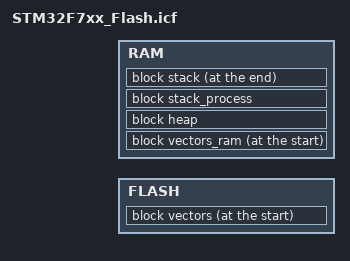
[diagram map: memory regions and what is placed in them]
/*********************************************************************
*                    SEGGER Microcontroller GmbH                     *
*                        The Embedded Experts                        *
**********************************************************************
*                                                                    *
*            (c) 2014 - 2021 SEGGER Microcontroller GmbH             *
*                                                                    *
*       www.segger.com     Support: support@segger.com               *
*                                                                    *
**********************************************************************
*                                                                    *
* All rights reserved.                                               *
*                                                                    *
* Redistribution and use in source and binary forms, with or         *
* without modification, are permitted provided that the following    *
* condition is met:                                                  *
*                                                                    *
* - Redistributions of source code must retain the above copyright   *
*   notice, this condition and the following disclaimer.             *
*                                                                    *
* THIS SOFTWARE IS PROVIDED BY THE COPYRIGHT HOLDERS AND             *
* CONTRIBUTORS "AS IS" AND ANY EXPRESS OR IMPLIED WARRANTIES,        *
* INCLUDING, BUT NOT LIMITED TO, THE IMPLIED WARRANTIES OF           *
* MERCHANTABILITY AND FITNESS FOR A PARTICULAR PURPOSE ARE           *
* DISCLAIMED. IN NO EVENT SHALL SEGGER Microcontroller BE LIABLE FOR *
* ANY DIRECT, INDIRECT, INCIDENTAL, SPECIAL, EXEMPLARY, OR           *
* CONSEQUENTIAL DAMAGES (INCLUDING, BUT NOT LIMITED TO, PROCUREMENT  *
* OF SUBSTITUTE GOODS OR SERVICES; LOSS OF USE, DATA, OR PROFITS;    *
* OR BUSINESS INTERRUPTION) HOWEVER CAUSED AND ON ANY THEORY OF      *
* LIABILITY, WHETHER IN CONTRACT, STRICT LIABILITY, OR TORT          *
* (INCLUDING NEGLIGENCE OR OTHERWISE) ARISING IN ANY WAY OUT OF THE  *
* USE OF THIS SOFTWARE, EVEN IF ADVISED OF THE POSSIBILITY OF SUCH   *
* DAMAGE.                                                            *
*                                                                    *
**********************************************************************
-------------------------- END-OF-HEADER -----------------------------

File    : STM32F7xx_Flash.icf
Purpose : STM32F7xx linker script for application placement in Flash,
          for use with the SEGGER Linker.
Maps    : STM32F722ICKx, STM32F722ICTx, STM32F722IEKx, STM32F722IETx, 
          STM32F722RCTx, STM32F722RETx, STM32F722VCTx, STM32F722VETx, 
          STM32F722ZCTx, STM32F722ZETx, STM32F723ICKx, STM32F723ICTx, 
          STM32F723IEKx, STM32F723IETx, STM32F723VEYx, STM32F723ZCIx, 
          STM32F723ZCTx, STM32F723ZEIx, STM32F723ZETx, STM32F730I8Kx, 
          STM32F730R8Tx, STM32F730V8Tx, STM32F730Z8Tx, STM32F732IEKx, 
          STM32F732IETx, STM32F732RETx, STM32F732VETx, STM32F732ZETx, 
          STM32F733IEKx, STM32F733IETx, STM32F733VETx, STM32F733VEYx, 
          STM32F733ZEKx, STM32F733ZETx, STM32F745IEKx, STM32F745IETx, 
          STM32F745IGKx, STM32F745IGTx, STM32F745VEHx, STM32F745VETx, 
          STM32F745VGHx, STM32F745VGTx, STM32F745ZETx, STM32F745ZGTx, 
          STM32F746BETx, STM32F746BGTx, STM32F746IEKx, STM32F746IETx, 
          STM32F746IGKx, STM32F746IGTx, STM32F746NEHx, STM32F746NGHx, 
          STM32F746VEHx, STM32F746VETx, STM32F746VGHx, STM32F746VGTx, 
          STM32F746ZETx, STM32F746ZEYx, STM32F746ZGTx, STM32F746ZGYx, 
          STM32F750N8Hx, STM32F750V8Tx, STM32F750Z8Tx, STM32F756BGTx, 
          STM32F756IGKx, STM32F756IGTx, STM32F756NGHx, STM32F756VGHx, 
          STM32F756VGTx, STM32F756ZGTx, STM32F756ZGYx, STM32F765BGTx, 
          STM32F765BITx, STM32F765IGKx, STM32F765IGTx, STM32F765IIKx, 
          STM32F765IITx, STM32F765NGHx, STM32F765NIHx, STM32F765VGTx, 
          STM32F765VITx, STM32F765ZGTx, STM32F765ZITx, STM32F767BGTx, 
          STM32F767BITx, STM32F767IGKx, STM32F767IGTx, STM32F767IIKx, 
          STM32F767IITx, STM32F767NGHx, STM32F767NIHx, STM32F767VGTx, 
          STM32F767VITx, STM32F767ZGTx, STM32F767ZITx, STM32F768AIYx, 
          STM32F769AGYx, STM32F769AIYx, STM32F769BGTx, STM32F769BITx, 
          STM32F769IGTx, STM32F769IITx, STM32F769NGHx, STM32F769NIHx, 
          STM32F777BITx, STM32F777IIKx, STM32F777IITx, STM32F777NIHx, 
          STM32F777VITx, STM32F777ZITx, STM32F778AIYx, STM32F779AIYx, 
          STM32F779BITx, STM32F779IITx, STM32F779NIHx
Literature:
  [1]  SEGGER Linker User Guide (https://www.segger.com/doc/UM20005_Linker.html)
  [2]  SEGGER Linker Section Placement (https://wiki.segger.com/SEGGER_Linker_Script_Files)
*/

define memory with size = 4G;

//
// Combined regions per memory type
//
define region FLASH = FLASH1;
define region RAM   = DTCM_RAM1 + RAM1;

//
// Block definitions
//
define block vectors                        { section .vectors };                                   // Vector table section
define block vectors_ram                    { section .vectors_ram };                               // Vector table section
define block ctors                          { section .ctors,     section .ctors.*, block with         alphabetical order { init_array } };
define block dtors                          { section .dtors,     section .dtors.*, block with reverse alphabetical order { fini_array } };
define block exidx                          { section .ARM.exidx, section .ARM.exidx.* };
define block tbss                           { section .tbss,      section .tbss.*  };
define block tdata                          { section .tdata,     section .tdata.* };
define block tls                            { block tbss, block tdata };
define block tdata_load                     { copy of block tdata };
define block heap  with size = __HEAPSIZE__,  alignment = 8, /* fill =0x00, */ readwrite access { };
define block stack_process with size = __STACKSIZE_PROCESS__, alignment = 8, /* fill =0xCD, */ readwrite access { };
define block stack with size = __STACKSIZE__, alignment = 8, /* fill =0xCD, */ readwrite access { };
//
// Explicit initialization settings for sections
// Packing options for initialize by copy: packing=auto/lzss/zpak/packbits
//
do not initialize                           { section .non_init, section .non_init.*, section .*.non_init, section .*.non_init.* };
do not initialize                           { section .no_init, section .no_init.*, section .*.no_init, section .*.no_init.* };   // Legacy sections, kept for backwards compatibility
do not initialize                           { section .noinit, section .noinit.*, section .*.noinit, section .*.noinit.* };       // Legacy sections, used by some SDKs/HALs
do not initialize                           { block vectors_ram };
initialize by copy with packing=auto        { section .data, section .data.*, section .*.data, section .*.data.* };               // Static data sections
initialize by copy with packing=auto        { section .fast, section .fast.* };                                                   // "RAM Code" sections
initialize by symbol __SEGGER_init_heap     { block heap  };                                        // Init the heap if there is one
initialize by symbol __SEGGER_init_ctors    { block ctors };                                        // Call constructors for global objects which need to be constructed before reaching main (if any). Make sure this is done after setting up heap.

//
// Explicit placement in FLASHn
//
place in ITCM_FLASH1                        { section .ITCM_FLASH1, section .ITCM_FLASH1.* };
place in FLASH1                             { section .FLASH1, section .FLASH1.* };
//
// FLASH Placement
//
place at start of FLASH                     { block vectors };                                      // Vector table section
place in FLASH with minimum size order      { block tdata_load,                                     // Thread-local-storage load image
                                              block exidx,                                          // ARM exception unwinding block
                                              block ctors,                                          // Constructors block
                                              block dtors,                                          // Destructors block
                                              readonly,                                             // Catch-all for readonly data (e.g. .rodata, .srodata)
                                              readexec                                              // Catch-all for (readonly) executable code (e.g. .text)
                                            };

//
// Explicit placement in RAMn
//
place in ITCM_RAM1                          { section .ITCM_RAM1, section .ITCM_RAM1.* };
place in DTCM_RAM1                          { section .DTCM_RAM1, section .DTCM_RAM1.* };
place in RAM1                               { section .RAM1, section .RAM1.* };


place in RAM1                               { section .fast, section .fast.*};                      // Place RAM Functions in executable region//
// RAM Placement
//
place at start of RAM                       { block vectors_ram };
place in RAM with auto order                { block tls,                                            // Thread-local-storage block
                                              readwrite,                                            // Catch-all for initialized/uninitialized data sections (e.g. .data, .noinit)
                                              zeroinit                                              // Catch-all for zero-initialized data sections (e.g. .bss)
                                            };
place in RAM                                { block heap };                                         // Heap reserved block
place in RAM                                { block stack_process };                                // Heap reserved block
place at end of RAM                         { block stack };                                        // Stack reserved block at the end
